# CY8C5666LTI_LP005 register map
File version: 0.1
CY8C56LP
Registers are 8-bit, read-write, no defined reset value unless marked. A register's access mark holds for its fields unless they carry their own. Offsets are from the block's base; lines under a group give offsets from that group; [hi:lo] are bit positions; {n}, {i} and the like mark numbered series; 'fields as' and 'values as' point back to an identical list; <NAME> marks a mode.

## Memory map
0x00000000 Sample_Hold_2
0x00000000 Comp_2
0x00000000 Sample_Hold_1
0x00000000 Comp_1
0x00000000 Sample_Hold_3
0x00000000 Comp_3
0x00000000 ADC_DelSig_1
0x00000000 Opamp_2
0x00000000 USBFS
0x00000000 SystemTickTimer
0x00000000 Opamp_3
0x00000000 Opamp_0
0x00000000 Sample_Hold_0
0x00000000 Comp_0
0x00000000 Opamp_1
0x4000646B USBFS_EP17_DMA_Done_SR
0x4000646C USBFS_EP8_DMA_Done_SR
0x4000646E Status_Reg_1
0x40006479 Clock_CIC_Running

## Clock_CIC_Running
Base 0x40006479
0x00 Clock_CIC_Running_CONTROL_REG

## Opamp_2
Base 0x00000000
0x400043A4 PM_ACT_CFG4 — Active Power Mode Configuration Register 4
  [3:0] EN_OPAMP — Enables subsystems during active power mode
    0=Blk_0 (Enables analog linear output buffer for Opamp block 0); 2=Blk_1 (Enables analog linear output buffer for Opamp block 1); 4=Blk_2 (Enables analog linear output buffer for Opamp block 2); 8=Blk_3 (Enables analog linear output buffer for Opamp block 3)
0x400043B4 PM_STBY_CFG4 — Standby Power Mode Configuration Register 4
  [3:0] EN_OPAMP — Enables subsystems during standby power mode
    values as PM_ACT_CFG4.EN_OPAMP
0x40004624 OPAMP__TR0 — Analog Output Buffer Trim Register 0
  [4:0] offset_trim — Offset Trim: 420uV typical step size; +/- 6.8mV offset trimmable range
0x40004625 OPAMP__TR1 — Analog Output Buffer Trim Register 1
0x4000585C OPAMP__CR — Analog Output Buffer Configuration Register
  [1:0] pwr_mode — Power Mode
    0=Default_Fast (Default Power mode Fast); 1=Slow (Power Mode Slow); 2=Medium (Power Mode Medium); 3=Fast (Power Mode Fast)
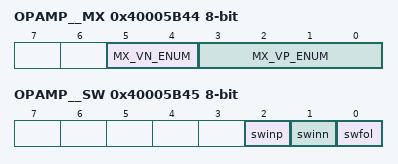
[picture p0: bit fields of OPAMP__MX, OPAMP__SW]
0x40005B44 OPAMP__MX — Analog Buffer Input Selection Register
  [5:4] MX_VN_ENUM — MUX select VN (Negative terminal input)
    0=OPAMP0_MX_VN_DEFAULT (Default - Not Connected (NC)); 1=OPAMP0_MX_VN_AG4 (MUX Selection AGL(4)); 2=OPAMP0_MX_VN_AG6 (MUX Selection AGL(6)); 3=OPAMP0_MX_VN_0x3 (Reserved (NC))
  [3:0] MX_VP_ENUM — MUX select VP (Positive terminal input)
    0=OPAMP0_MX_VP_DEFAULT (Default - Not Connected (NC)); {v}=OPAMP0_MX_VP_AG{v+3} (MUX Selection AGL({v+3})) (v=1..4); {v}=OPAMP0_MX_VP_ABUS{v-5} (MUX Selection ABUSL({v-5})) (v=5..8); 9=OPAMP0_MX_VP_VREF (MUX Selection: OPAMP Voltage Reference); {v}=OPAMP0_MX_VP_H_{0x0+v} (Reserved (NC)) (v=10..15)
0x40005B45 OPAMP__SW — Analog Buffer Routing Switch Register
  [2] swinp — Switch Enable Positive Input
  [1] swinn — Switch Enable Negative Input
  [0] swfol — Switch Enable Follow

## USBFS
Base 0x00000000
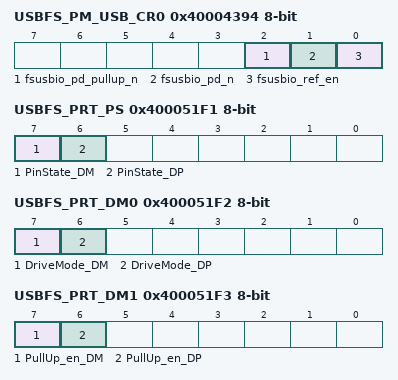
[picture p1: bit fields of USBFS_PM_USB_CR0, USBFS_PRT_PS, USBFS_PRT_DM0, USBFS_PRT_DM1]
0x40004394 USBFS_PM_USB_CR0 — USB Power Mode Control Register 0
  [2] fsusbio_pd_pullup_n, [1] fsusbio_pd_n, [0] fsusbio_ref_en
0x400043A5 USBFS_PM_ACT_CFG — Active Power Mode Configuration Register
0x400043B5 USBFS_PM_STBY_CFG — Standby Power Mode Configuration Register
0x400051F1 USBFS_PRT_PS — Port Pin State Register
  [7] PinState_DM ro, [6] PinState_DP ro
0x400051F2 USBFS_PRT_DM0 — Port Drive Mode Register
  [7] DriveMode_DM, [6] DriveMode_DP
0x400051F3 USBFS_PRT_DM1 — Port Drive Mode Register
  [7] PullUp_en_DM, [6] PullUp_en_DP
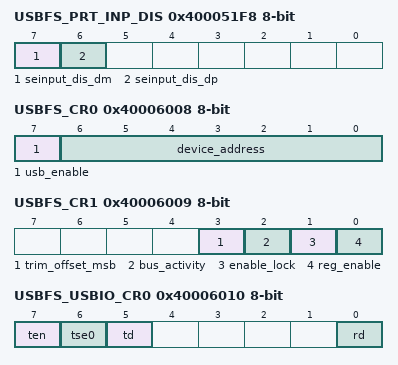
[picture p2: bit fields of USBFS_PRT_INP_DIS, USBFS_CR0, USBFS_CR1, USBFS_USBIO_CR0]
0x400051F8 USBFS_PRT_INP_DIS — Input buffer disable override
  [7] seinput_dis_dm, [6] seinput_dis_dp
0x40006000 USBFS_EP0_DR0 — bmRequestType
0x40006001 USBFS_EP0_DR1 — bRequest
0x40006002 USBFS_EP0_DR2 — wValueLo
0x40006003 USBFS_EP0_DR3 — wValueHi
0x40006004 USBFS_EP0_DR4 — wIndexLo
0x40006005 USBFS_EP0_DR5 — wIndexHi
0x40006006 USBFS_EP0_DR6 — lengthLo
0x40006007 USBFS_EP0_DR7 — lengthHi
0x40006008 USBFS_CR0 — USB Control Register 0
  [7] usb_enable, [6:0] device_address ro
0x40006009 USBFS_CR1 — USB Control Register 1
  [3] trim_offset_msb, [2] bus_activity, [1] enable_lock, [0] reg_enable
{0x40005FFE+0x10*i} USBFS_SIE_EP{i}_CR0 (i=1..8) — The Endpoint{i} Control Register
0x40006010 USBFS_USBIO_CR0 — USBIO Control Register 0
  [7] ten, [6] tse0, [5] td, [0] rd ro
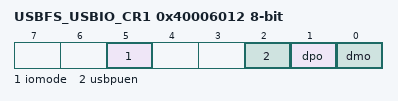
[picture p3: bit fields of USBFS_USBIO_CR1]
0x40006012 USBFS_USBIO_CR1 — USBIO Control Register 1
  [5] iomode, [2] usbpuen, [1] dpo ro, [0] dmo ro
0x4000608C USBFS_BUF_SIZE — Dedicated Endpoint Buffer Size Register
0x4000608E USBFS_EP_ACTIVE — Endpoint Active Indication Register
0x4000608F USBFS_EP_TYPE — Endpoint Type (IN/OUT) Indication
0x4000609D USBFS_USB_CLK_EN — USB Block Clock Enable Register
